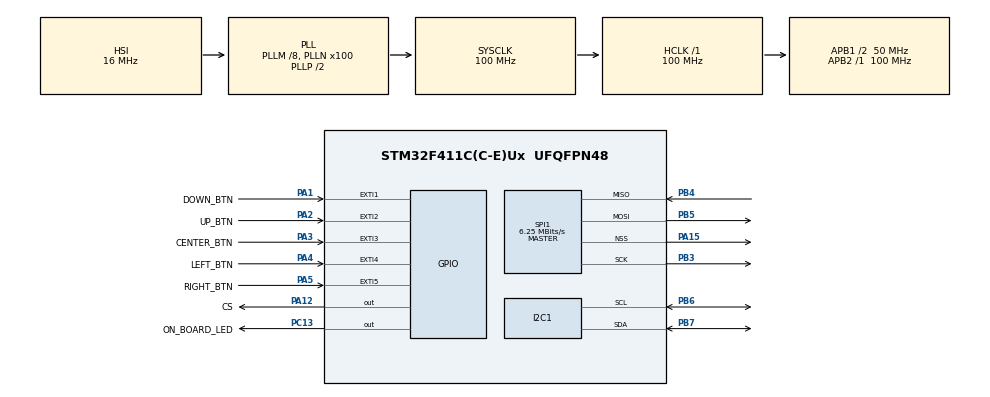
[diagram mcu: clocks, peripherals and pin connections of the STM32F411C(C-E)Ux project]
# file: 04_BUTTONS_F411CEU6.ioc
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Mcu.Family=STM32F4
Mcu.Name=STM32F411C(C-E)Ux
Mcu.Package=UFQFPN48
NVIC.EXTI1_IRQn=true\:0\:0\:false\:false\:true\:true\:true\:true
NVIC.EXTI2_IRQn=true\:0\:0\:false\:false\:true\:true\:true\:true
NVIC.EXTI3_IRQn=true\:0\:0\:false\:false\:true\:true\:true\:true
NVIC.EXTI4_IRQn=true\:0\:0\:false\:false\:true\:true\:true\:true
NVIC.EXTI9_5_IRQn=true\:0\:0\:false\:false\:true\:true\:true\:true
NVIC.I2C1_ER_IRQn=true\:0\:0\:false\:false\:true\:true\:true\:true
NVIC.I2C1_EV_IRQn=true\:0\:0\:false\:false\:true\:true\:true\:true
NVIC.PriorityGroup=NVIC_PRIORITYGROUP_4
NVIC.SPI1_IRQn=true\:0\:0\:false\:false\:true\:true\:true\:true
PA1.GPIO_Label=DOWN_BTN
PA1.GPIO_ModeDefaultEXTI=GPIO_MODE_IT_FALLING
PA1.GPIO_PuPd=GPIO_PULLUP
PA1.Signal=GPXTI1
PA12.GPIO_Label=CS
PA12.Signal=GPIO_Output
PA13.Mode=Serial_Wire
PA13.Signal=SYS_JTMS-SWDIO
PA14.Mode=Serial_Wire
PA14.Signal=SYS_JTCK-SWCLK
PA15.Mode=NSS_Signal_Hard_Output
PA15.Signal=SPI1_NSS
PA2.GPIO_Label=UP_BTN
PA2.GPIO_ModeDefaultEXTI=GPIO_MODE_IT_FALLING
PA2.GPIO_PuPd=GPIO_PULLUP
PA2.Signal=GPXTI2
PA3.GPIO_Label=CENTER_BTN
PA3.GPIO_ModeDefaultEXTI=GPIO_MODE_IT_FALLING
PA3.GPIO_PuPd=GPIO_PULLUP
PA3.Signal=GPXTI3
PA4.GPIO_Label=LEFT_BTN
PA4.GPIO_ModeDefaultEXTI=GPIO_MODE_IT_FALLING
PA4.GPIO_PuPd=GPIO_PULLUP
PA4.Signal=GPXTI4
PA5.GPIO_Label=RIGHT_BTN
PA5.GPIO_ModeDefaultEXTI=GPIO_MODE_IT_FALLING
PA5.GPIO_PuPd=GPIO_PULLUP
PA5.Signal=GPXTI5
PB3.Mode=Full_Duplex_Master
PB3.Signal=SPI1_SCK
PB4.Mode=Full_Duplex_Master
PB4.Signal=SPI1_MISO
PB5.Mode=Full_Duplex_Master
PB5.Signal=SPI1_MOSI
PB6.Mode=I2C
PB6.Signal=I2C1_SCL
PB7.Mode=I2C
PB7.Signal=I2C1_SDA
PC13-ANTI_TAMP.GPIO_Label=ON_BOARD_LED
PC13-ANTI_TAMP.Signal=GPIO_Output
PC14-OSC32_IN.Mode=LSE-External-Oscillator
PC14-OSC32_IN.Signal=RCC_OSC32_IN
PC15-OSC32_OUT.Mode=LSE-External-Oscillator
PC15-OSC32_OUT.Signal=RCC_OSC32_OUT
PH0\ -\ OSC_IN.Mode=HSE-External-Oscillator
PH0\ -\ OSC_IN.Signal=RCC_OSC_IN
PH1\ -\ OSC_OUT.Mode=HSE-External-Oscillator
PH1\ -\ OSC_OUT.Signal=RCC_OSC_OUT
ProjectManager.HeapSize=0x200
ProjectManager.StackSize=0x400
ProjectManager.TargetToolchain=STM32CubeIDE
RCC.48MHZClocksFreq_Value=50000000
RCC.AHBFreq_Value=100000000
RCC.APB1CLKDivider=RCC_HCLK_DIV2
RCC.APB1Freq_Value=50000000
RCC.APB1TimFreq_Value=100000000
RCC.APB2Freq_Value=100000000
RCC.APB2TimFreq_Value=100000000
RCC.CortexFreq_Value=100000000
RCC.HCLKFreq_Value=100000000
RCC.HSE_VALUE=25000000
RCC.HSI_VALUE=16000000
RCC.PLLM=8
RCC.PLLN=100
RCC.SYSCLKFreq_VALUE=100000000
RCC.SYSCLKSource=RCC_SYSCLKSOURCE_PLLCLK
RCC.VCOOutputFreq_Value=200000000
SPI1.BaudRatePrescaler=SPI_BAUDRATEPRESCALER_16
SPI1.CalculateBaudRate=6.25 MBits/s
SPI1.DataSize=SPI_DATASIZE_16BIT
SPI1.Direction=SPI_DIRECTION_2LINES
SPI1.Mode=SPI_MODE_MASTER
SPI1.VirtualNSS=VM_NSSHARD
SPI1.VirtualType=VM_MASTER
board=custom

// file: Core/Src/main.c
/* USER CODE BEGIN Header */
/**
  ******************************************************************************
  * @file           : main.c
  * @brief          : Main program body
  ******************************************************************************
  * @attention
  *
  * Copyright (c) 2025 STMicroelectronics.
  * All rights reserved.
  *
  * This software is licensed under terms that can be found in the LICENSE file
  * in the root directory of this software component.
  * If no LICENSE file comes with this software, it is provided AS-IS.
  *
  ******************************************************************************
  */
/* USER CODE END Header */
#include "main.h"

/* USER CODE BEGIN Includes */
#include "buttons.h"
/* USER CODE END Includes */

I2C_HandleTypeDef hi2c1;

SPI_HandleTypeDef hspi1;

void SystemClock_Config(void);
static void MX_GPIO_Init(void);
static void MX_I2C1_Init(void);
static void MX_SPI1_Init(void);

int main(void)
{

  /* MCU Configuration--------------------------------------------------------*/

  /* Reset of all peripherals, Initializes the Flash interface and the Systick. */
  HAL_Init();

  /* Configure the system clock */
  SystemClock_Config();

  /* Initialize all configured peripherals */
  MX_GPIO_Init();
  MX_I2C1_Init();
  MX_SPI1_Init();
  /* USER CODE BEGIN 2 */
  Buttons_Init();
  /* USER CODE END 2 */

  /* Infinite loop */
  while (1)
  {

    /* USER CODE BEGIN 3 */
	  Button_Debouncing();
  }
  /* USER CODE END 3 */
}

void SystemClock_Config(void)
{
  RCC_OscInitTypeDef RCC_OscInitStruct = {0};
  RCC_ClkInitTypeDef RCC_ClkInitStruct = {0};

  /** Configure the main internal regulator output voltage
  */
  __HAL_RCC_PWR_CLK_ENABLE();
  __HAL_PWR_VOLTAGESCALING_CONFIG(PWR_REGULATOR_VOLTAGE_SCALE1);

  /** Initializes the RCC Oscillators according to the specified parameters
  * in the RCC_OscInitTypeDef structure.
  */
  RCC_OscInitStruct.OscillatorType = RCC_OSCILLATORTYPE_HSI;
  RCC_OscInitStruct.HSIState = RCC_HSI_ON;
  RCC_OscInitStruct.HSICalibrationValue = RCC_HSICALIBRATION_DEFAULT;
  RCC_OscInitStruct.PLL.PLLState = RCC_PLL_ON;
  RCC_OscInitStruct.PLL.PLLSource = RCC_PLLSOURCE_HSI;
  RCC_OscInitStruct.PLL.PLLM = 8;
  RCC_OscInitStruct.PLL.PLLN = 100;
  RCC_OscInitStruct.PLL.PLLP = RCC_PLLP_DIV2;
  RCC_OscInitStruct.PLL.PLLQ = 4;
  if (HAL_RCC_OscConfig(&RCC_OscInitStruct) != HAL_OK)
  {
    Error_Handler();
  }

  /** Initializes the CPU, AHB and APB buses clocks
  */
  RCC_ClkInitStruct.ClockType = RCC_CLOCKTYPE_HCLK|RCC_CLOCKTYPE_SYSCLK
                              |RCC_CLOCKTYPE_PCLK1|RCC_CLOCKTYPE_PCLK2;
  RCC_ClkInitStruct.SYSCLKSource = RCC_SYSCLKSOURCE_PLLCLK;
  RCC_ClkInitStruct.AHBCLKDivider = RCC_SYSCLK_DIV1;
  RCC_ClkInitStruct.APB1CLKDivider = RCC_HCLK_DIV2;
  RCC_ClkInitStruct.APB2CLKDivider = RCC_HCLK_DIV1;

  if (HAL_RCC_ClockConfig(&RCC_ClkInitStruct, FLASH_LATENCY_3) != HAL_OK)
  {
    Error_Handler();
  }
}

static void MX_I2C1_Init(void)
{

  hi2c1.Instance = I2C1;
  hi2c1.Init.ClockSpeed = 100000;
  hi2c1.Init.DutyCycle = I2C_DUTYCYCLE_2;
  hi2c1.Init.OwnAddress1 = 0;
  hi2c1.Init.AddressingMode = I2C_ADDRESSINGMODE_7BIT;
  hi2c1.Init.DualAddressMode = I2C_DUALADDRESS_DISABLE;
  hi2c1.Init.OwnAddress2 = 0;
  hi2c1.Init.GeneralCallMode = I2C_GENERALCALL_DISABLE;
  hi2c1.Init.NoStretchMode = I2C_NOSTRETCH_DISABLE;
  if (HAL_I2C_Init(&hi2c1) != HAL_OK)
  {
    Error_Handler();
  }

}

static void MX_SPI1_Init(void)
{

  /* SPI1 parameter configuration*/
  hspi1.Instance = SPI1;
  hspi1.Init.Mode = SPI_MODE_MASTER;
  hspi1.Init.Direction = SPI_DIRECTION_2LINES;
  hspi1.Init.DataSize = SPI_DATASIZE_16BIT;
  hspi1.Init.CLKPolarity = SPI_POLARITY_LOW;
  hspi1.Init.CLKPhase = SPI_PHASE_1EDGE;
  hspi1.Init.NSS = SPI_NSS_HARD_OUTPUT;
  hspi1.Init.BaudRatePrescaler = SPI_BAUDRATEPRESCALER_16;
  hspi1.Init.FirstBit = SPI_FIRSTBIT_MSB;
  hspi1.Init.TIMode = SPI_TIMODE_DISABLE;
  hspi1.Init.CRCCalculation = SPI_CRCCALCULATION_DISABLE;
  hspi1.Init.CRCPolynomial = 10;
  if (HAL_SPI_Init(&hspi1) != HAL_OK)
  {
    Error_Handler();
  }

}

static void MX_GPIO_Init(void)
{
  GPIO_InitTypeDef GPIO_InitStruct = {0};

  /* GPIO Ports Clock Enable */
  __HAL_RCC_GPIOC_CLK_ENABLE();
  __HAL_RCC_GPIOH_CLK_ENABLE();
  __HAL_RCC_GPIOA_CLK_ENABLE();
  __HAL_RCC_GPIOB_CLK_ENABLE();

  /*Configure GPIO pin Output Level */
  HAL_GPIO_WritePin(ON_BOARD_LED_GPIO_Port, ON_BOARD_LED_Pin, GPIO_PIN_RESET);

  /*Configure GPIO pin Output Level */
  HAL_GPIO_WritePin(CS_GPIO_Port, CS_Pin, GPIO_PIN_RESET);

  /*Configure GPIO pin : ON_BOARD_LED_Pin */
  GPIO_InitStruct.Pin = ON_BOARD_LED_Pin;
  GPIO_InitStruct.Mode = GPIO_MODE_OUTPUT_PP;
  GPIO_InitStruct.Pull = GPIO_NOPULL;
  GPIO_InitStruct.Speed = GPIO_SPEED_FREQ_LOW;
  HAL_GPIO_Init(ON_BOARD_LED_GPIO_Port, &GPIO_InitStruct);

  /*Configure GPIO pins : DOWN_BTN_Pin UP_BTN_Pin CENTER_BTN_Pin LEFT_BTN_Pin
                           RIGHT_BTN_Pin */
  GPIO_InitStruct.Pin = DOWN_BTN_Pin|UP_BTN_Pin|CENTER_BTN_Pin|LEFT_BTN_Pin
                          |RIGHT_BTN_Pin;
  GPIO_InitStruct.Mode = GPIO_MODE_IT_FALLING;
  GPIO_InitStruct.Pull = GPIO_PULLUP;
  HAL_GPIO_Init(GPIOA, &GPIO_InitStruct);

  /*Configure GPIO pin : CS_Pin */
  GPIO_InitStruct.Pin = CS_Pin;
  GPIO_InitStruct.Mode = GPIO_MODE_OUTPUT_PP;
  GPIO_InitStruct.Pull = GPIO_NOPULL;
  GPIO_InitStruct.Speed = GPIO_SPEED_FREQ_LOW;
  HAL_GPIO_Init(CS_GPIO_Port, &GPIO_InitStruct);

  /* EXTI interrupt init*/
  HAL_NVIC_SetPriority(EXTI1_IRQn, 0, 0);
  HAL_NVIC_EnableIRQ(EXTI1_IRQn);

  HAL_NVIC_SetPriority(EXTI2_IRQn, 0, 0);
  HAL_NVIC_EnableIRQ(EXTI2_IRQn);

  HAL_NVIC_SetPriority(EXTI3_IRQn, 0, 0);
  HAL_NVIC_EnableIRQ(EXTI3_IRQn);

  HAL_NVIC_SetPriority(EXTI4_IRQn, 0, 0);
  HAL_NVIC_EnableIRQ(EXTI4_IRQn);

  HAL_NVIC_SetPriority(EXTI9_5_IRQn, 0, 0);
  HAL_NVIC_EnableIRQ(EXTI9_5_IRQn);

}

void Error_Handler(void)
{
  __disable_irq();
  while (1)
  {
  }
}
